# WB32F10x register map
File version: 1.2
CPU: CM3 r2p0, little endian, MPU, no FPU, 4 interrupt priority bits
Registers are 32-bit, read-write, reset 0x0 unless marked. A register's access mark holds for its fields unless they carry their own. Offsets are from the block's base; [hi:lo] are bit positions; {n}, {i} and the like mark numbered series; 'fields as' and 'values as' point back to an identical list.

## DMAC1 — Direct memory access controller1 1
Base 0x40007C00
Same registers: DMAC2 0x4000FC00
{0x0+0x58*i} SAR{i} (i=0..2) — Source address register for channel {i}
  [31:0] SAR — Source address
{0x8+0x58*i} DAR{i} (i=0..2) — Destination address register for channel {i}
  [31:0] DAR — Destination address
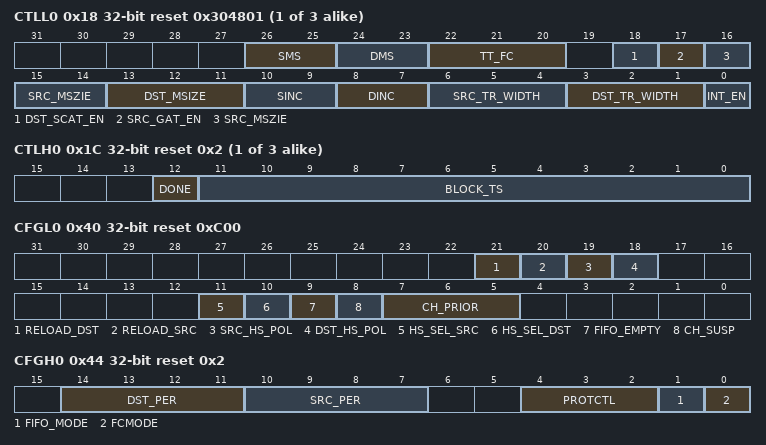
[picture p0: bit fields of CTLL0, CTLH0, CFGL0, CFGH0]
{0x18+0x58*i} CTLL{i} reset 0x304801 (i=0..2) — Control low register for channel {i}
  [26:25] SMS — Source master interface specification
  [24:23] DMS — Destination master interface specification
  [22:20] TT_FC — Transfer type and flow control
  [18] DST_SCAT_EN — Destination scatter enable
  [17] SRC_GAT_EN — Source gather enable
  [16:14] SRC_MSZIE — Source burst transaction data width
  [13:11] DST_MSIZE — Destination burst transaction data width
  [10:9] SINC — Source address increment
  [8:7] DINC — Destination address increment
  [6:4] SRC_TR_WIDTH — Source transfer data width
  [3:1] DST_TR_WIDTH — Destination transfer data width
  [0] INT_EN — Interrupt enable
{0x1C+0x58*i} CTLH{i} reset 0x2 (i=0..2) — Control high register for channel {i}
  [12] DONE — Check if the block transfer is done by polling this bit
  [11:0] BLOCK_TS — Block transfer size
0x40 CFGL0 reset 0xC00 — Channel configuration low register for channel 0
  [21] RELOAD_DST — Destination address register automatically reload
  [20] RELOAD_SRC — Source address register automatically reload
  [19] SRC_HS_POL — Source handshaking polarity
  [18] DST_HS_POL — Destination handshaking polarity
  [11] HS_SEL_SRC — Handshaking selection of source
  [10] HS_SEL_DST — Handshaking selection of destination
  [9] FIFO_EMPTY
  [8] CH_SUSP — Channel suspend
  [7:5] CH_PRIOR — Channel priority
0x44 CFGH0 reset 0x2 — Channel configuration low register for channel 0
  [14:11] DST_PER — Destination handshaking of specified peripheral
  [10:7] SRC_PER — Source handshaking of specified peripheral
  [4:2] PROTCTL — Protection control for AMBA peripheral
  [1] FIFO_MODE
  [0] FCMODE — Flow control mode
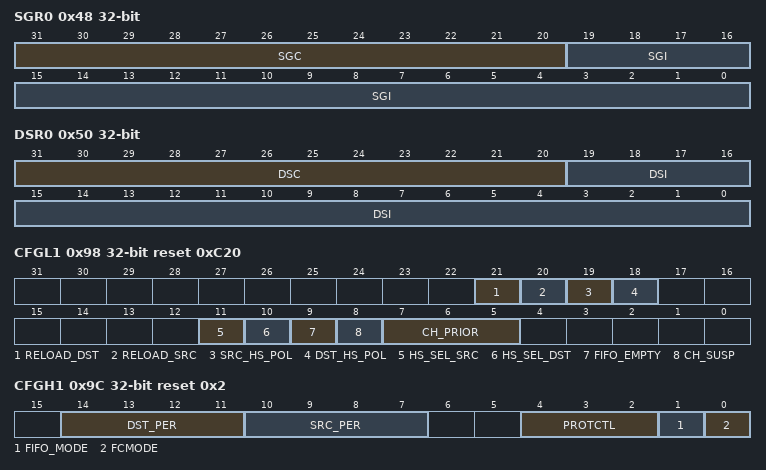
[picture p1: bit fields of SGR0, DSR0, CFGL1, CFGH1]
0x48 SGR0 — Source gather register
  [31:20] SGC — Source gather counter
  [19:0] SGI — Source gather interval
0x50 DSR0 — Destination scatter register
  [31:20] DSC — Destination scatter counter
  [19:0] DSI — Destination scatter interval
0x98 CFGL1 reset 0xC20 — Configuration low register for channel 1
  fields as CFGL0
0x9C CFGH1 reset 0x2 — Configuration low register for channel 1
  [14:11] DST_PER — Destination handshaking of specified peripheral
  [10:7] SRC_PER — source handshaking of specified peripheral
  [4:2] PROTCTL — Protection control for AMBA peripheral
  [1] FIFO_MODE
  [0] FCMODE — Flow control mode
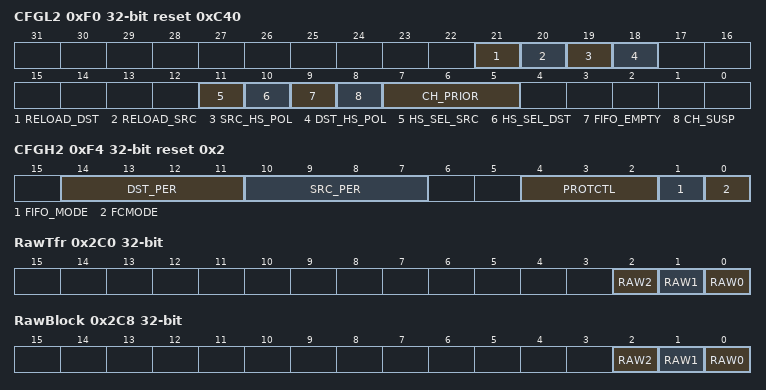
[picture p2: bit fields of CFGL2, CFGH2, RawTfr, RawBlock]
0xF0 CFGL2 reset 0xC40 — Configuration low register for channel 2
  fields as CFGL0
0xF4 CFGH2 reset 0x2 — Configuration low register for channel 2
  fields as CFGH1
0x2C0 RawTfr ro — Transfer interrupt raw status register
  [2] RAW2 — Transfer interrupt raw status for channel 2
  [1] RAW1 — Transfer interrupt raw status for channel 1
  [0] RAW0 — Transfer interrupt raw status for channel 0
0x2C8 RawBlock ro — Block transfer interrupt raw status register
  [2] RAW2 — Block transfer interrupt raw status for channel 2
  [1] RAW1 — Block transfer interrupt raw status for channel 1
  [0] RAW0 — Block transfer interrupt raw status for channel 0
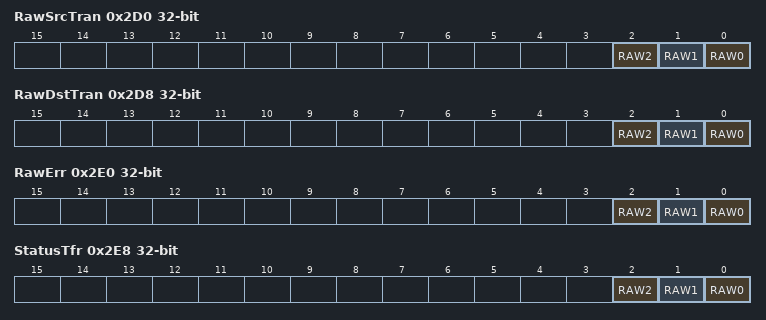
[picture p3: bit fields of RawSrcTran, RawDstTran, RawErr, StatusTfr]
0x2D0 RawSrcTran ro — Source transaction raw status register
  [2] RAW2 — Source transaction raw status for channel 2
  [1] RAW1 — Source transaction raw status for channel 1
  [0] RAW0 — Source transaction raw status for channel 0
0x2D8 RawDstTran ro — Destination transaction interrupt raw status register
  [2] RAW2 — Destination transaction interrupt raw status for channel 2
  [1] RAW1 — Destination transaction interrupt raw status for channel 1
  [0] RAW0 — Destination transaction interrupt raw status for channel 0
0x2E0 RawErr ro — Error interrupt raw status register
  [2] RAW2 — Error interrupt raw status for channel 2
  [1] RAW1 — Error interrupt raw status for channel 1
  [0] RAW0 — Error interrupt raw status for channel 0
0x2E8 StatusTfr ro — Transfer interrupt status register
  [2] RAW2 — Transfer interrupt status for channel 2
  [1] RAW1 — Transfer interrupt status for channel 1
  [0] RAW0 — Transfer interrupt status for channel 0
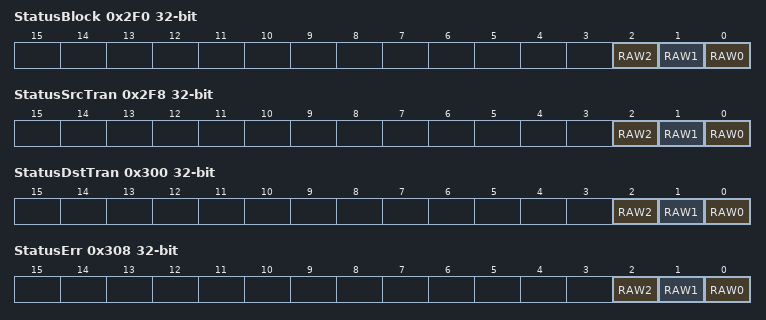
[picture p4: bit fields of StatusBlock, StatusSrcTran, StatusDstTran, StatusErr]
0x2F0 StatusBlock ro — Block transfer interrupt status register
  [2] RAW2 — Block transfer interrupt status for channel 2
  [1] RAW1 — Block transfer interrupt status for channel 1
  [0] RAW0 — Block transfer interrupt status for channel 0
0x2F8 StatusSrcTran ro — Source transaction interrupt status register
  [2] RAW2 — Source transaction interrupt status for channel 2
  [1] RAW1 — Source transaction interrupt status for channel 1
  [0] RAW0 — Source transaction interrupt status for channel 0
0x300 StatusDstTran ro — Destination transaction interrupt status register
  [2] RAW2 — Destination transaction interrupt status for channel 2
  [1] RAW1 — Destination transaction interrupt status for channel 1
  [0] RAW0 — Destination transaction interrupt status for channel 0
0x308 StatusErr ro — Error interrupt status register
  [2] RAW2 — Error interrupt status for channel 2
  [1] RAW1 — Error interrupt status for channel 1
  [0] RAW0 — Error interrupt status for channel 0
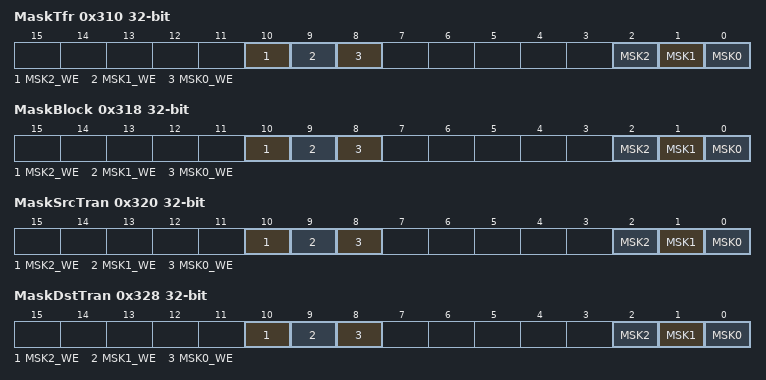
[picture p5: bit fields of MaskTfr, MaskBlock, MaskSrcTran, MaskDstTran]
0x310 MaskTfr — Transfer interrupt mask register
  [10] MSK2_WE — Transfer interrupt mask write enable for channel 2
  [9] MSK1_WE — Transfer interrupt mask write enable for channel 1
  [8] MSK0_WE — Transfer interrupt mask write enable for channel 0
  [2] MSK2 — Transfer interrupt mask for channel 2
  [1] MSK1 — Transfer interrupt mask for channel 1
  [0] MSK0 — Transfer interrupt mask for channel 0
0x318 MaskBlock — Block transfer interrupt mask register
  [10] MSK2_WE — Block transfer interrupt mask write enable for channel 2
  [9] MSK1_WE — Block transfer interrupt mask write enable for channel 1
  [8] MSK0_WE — Block transfer interrupt mask write enable for channel 0
  [2] MSK2 — Block transfer interrupt mask for channel 2
  [1] MSK1 — Block transfer interrupt mask for channel 1
  [0] MSK0 — Block transfer interrupt mask for channel 0
0x320 MaskSrcTran — Source transaction interrupt mask register
  [10] MSK2_WE — Source transaction interrupt mask write enable for channel 2
  [9] MSK1_WE — Source transaction interrupt mask write enable for channel 1
  [8] MSK0_WE — Source transaction interrupt mask write enable for channel 0
  [2] MSK2 — Source transaction interrupt mask for channel 2
  [1] MSK1 — Source transaction interrupt mask for channel 1
  [0] MSK0 — Source transaction interrupt mask for channel 0
0x328 MaskDstTran — Destination transaction interrupt mask register
  [10] MSK2_WE — Destination transaction interrupt mask write enable for channel 2
  [9] MSK1_WE — Destination transaction interrupt mask write enable for channel 1
  [8] MSK0_WE — Destination transaction interrupt mask write enable for channel 0
  [2] MSK2 — Destination transaction interrupt mask for channel 2
  [1] MSK1 — Destination transaction interrupt mask for channel 1
  [0] MSK0 — Destination transaction interrupt mask for channel 0
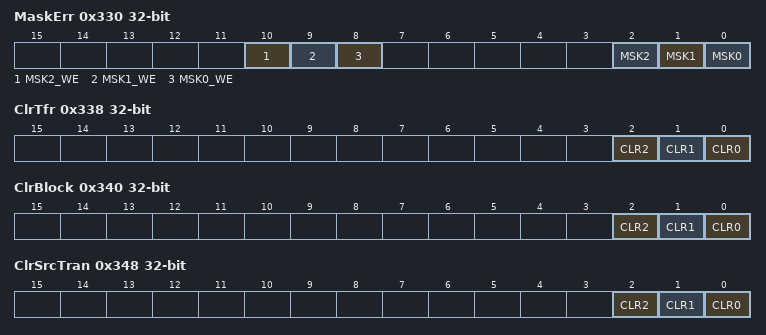
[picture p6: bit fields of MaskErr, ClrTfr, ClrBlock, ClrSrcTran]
0x330 MaskErr — Error interrupt mask register
  [10] MSK2_WE — Error interrupt mask write enable for channel 2
  [9] MSK1_WE — Error interrupt mask write enable for channel 1
  [8] MSK0_WE — Error interrupt mask write enable for channel 0
  [2] MSK2 — Error interrupt mask for channel 2
  [1] MSK1 — Error interrupt mask for channel 1
  [0] MSK0 — Error interrupt mask for channel 0
0x338 ClrTfr wo — Transfer interrupt clear register
  [2] CLR2 — Clear transfer interrupt for channel 2
  [1] CLR1 — Clear transfer interrupt for channel 1
  [0] CLR0 — Clear transfer interrupt for channel 0
0x340 ClrBlock wo — Block transfer interrupt clear register
  [2] CLR2 — Clear block transfer interrupt for channel 2
  [1] CLR1 — Clear block transfer interrupt for channel 1
  [0] CLR0 — Clear block transfer interrupt for channel 0
0x348 ClrSrcTran wo — Source transaction interrupt clear register
  [2] CLR2 — Clear Source transaction interrupt for channel 2
  [1] CLR1 — Clear Source transaction interrupt for channel 1
  [0] CLR0 — Clear Source transaction interrupt for channel 0
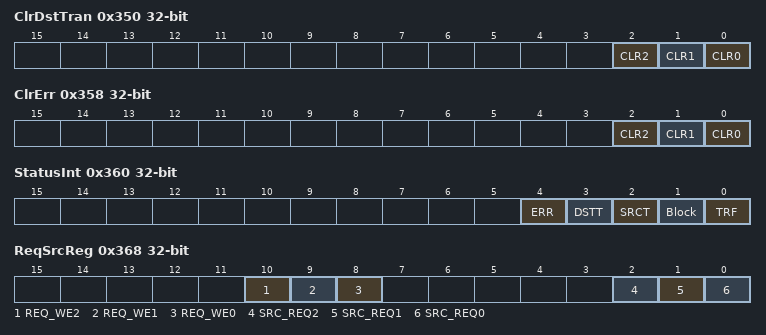
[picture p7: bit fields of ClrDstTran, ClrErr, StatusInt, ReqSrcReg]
0x350 ClrDstTran wo — Destination transaction interrupt clear register
  [2] CLR2 — Clear Destination transaction interrupt for channel 2
  [1] CLR1 — Clear Destination transaction interrupt for channel 1
  [0] CLR0 — Clear Destination transaction interrupt for channel 0
0x358 ClrErr wo — Error interrupt clear register
  [2] CLR2 — Clear error interrupt for channel 2
  [1] CLR1 — Clear error interrupt for channel 1
  [0] CLR0 — Clear error interrupt for channel 0
0x360 StatusInt ro — DMAC interrupt status register
  [4] ERR — Error interrupt flag
  [3] DSTT — Destination transaction interrupt flag
  [2] SRCT — Source transaction interrupt flag
  [1] Block — Block transfer interrupt flag
  [0] TRF — Transfer complete interrupt flag
0x368 ReqSrcReg — Source request register
  [10] REQ_WE2 — Source request write enable for channel 0
  [9] REQ_WE1 — Source request write enable for channel 0
  [8] REQ_WE0 — Source request write enable for channel 0
  [2] SRC_REQ2 — Source request for channel 2
  [1] SRC_REQ1 — Source request for channel 1
  [0] SRC_REQ0 — Source request for channel 0
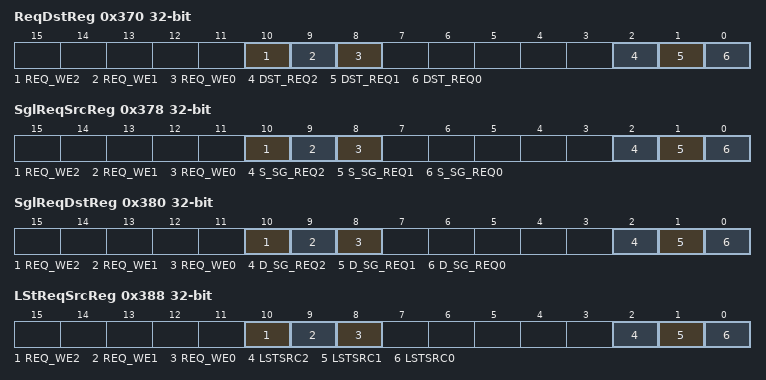
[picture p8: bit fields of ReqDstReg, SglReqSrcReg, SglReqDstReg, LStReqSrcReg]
0x370 ReqDstReg — Destination request register
  [10] REQ_WE2 — Destination request write enable for channel 0
  [9] REQ_WE1 — Destination request write enable for channel 0
  [8] REQ_WE0 — Destination request write enable for channel 0
  [2] DST_REQ2 — Destination request for channel 2
  [1] DST_REQ1 — Destination request for channel 1
  [0] DST_REQ0 — Destination request for channel 0
0x378 SglReqSrcReg — Source single request register
  [10] REQ_WE2 — Source single request write enable for channel 0
  [9] REQ_WE1 — Source single request write enable for channel 0
  [8] REQ_WE0 — Source single request write enable for channel 0
  [2] S_SG_REQ2 — Source single request for channel 2
  [1] S_SG_REQ1 — Source single request for channel 1
  [0] S_SG_REQ0 — Source single request for channel 0
0x380 SglReqDstReg — Destination single request register
  [10] REQ_WE2 — Destination single request write enable for channel 0
  [9] REQ_WE1 — Destination single request write enable for channel 0
  [8] REQ_WE0 — Destination single request write enable for channel 0
  [2] D_SG_REQ2 — Destination single request for channel 2
  [1] D_SG_REQ1 — Destination single request for channel 1
  [0] D_SG_REQ0 — Destination single request for channel 0
0x388 LStReqSrcReg — Source last request register
  [10] REQ_WE2 — Source last request write enable for channel 0
  [9] REQ_WE1 — Source last request write enable for channel 0
  [8] REQ_WE0 — Source last request write enable for channel 0
  [2] LSTSRC2 — Source last request for channel 2
  [1] LSTSRC1 — Source last request for channel 1
  [0] LSTSRC0 — Source last request for channel 0
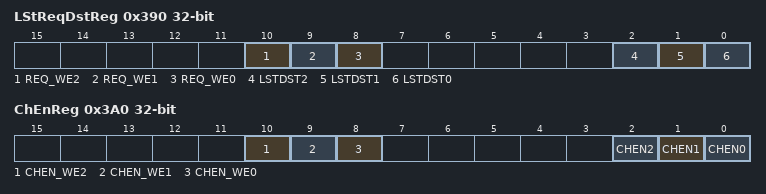
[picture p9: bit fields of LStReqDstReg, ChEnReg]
0x390 LStReqDstReg — Destination last request register
  [10] REQ_WE2 — Destination last request write enable for channel 0
  [9] REQ_WE1 — Destination last request write enable for channel 0
  [8] REQ_WE0 — Destination last request write enable for channel 0
  [2] LSTDST2 — Destination last request for channel 2
  [1] LSTDST1 — Destination last request for channel 1
  [0] LSTDST0 — Destination last request for channel 0
0x398 DmaCfgReg — DMA configuration register
  [0] DMA_EN — DMA enable
0x3A0 ChEnReg — Channel enable register
  [10] CHEN_WE2 — Channel 2 write enable
  [9] CHEN_WE1 — Channel 1 write enable
  [8] CHEN_WE0 — Channel 0 write enable
  [2] CHEN2 — Channel 2 enable
  [1] CHEN1 — Channel 1 enable
  [0] CHEN0 — Channel 0 enable
